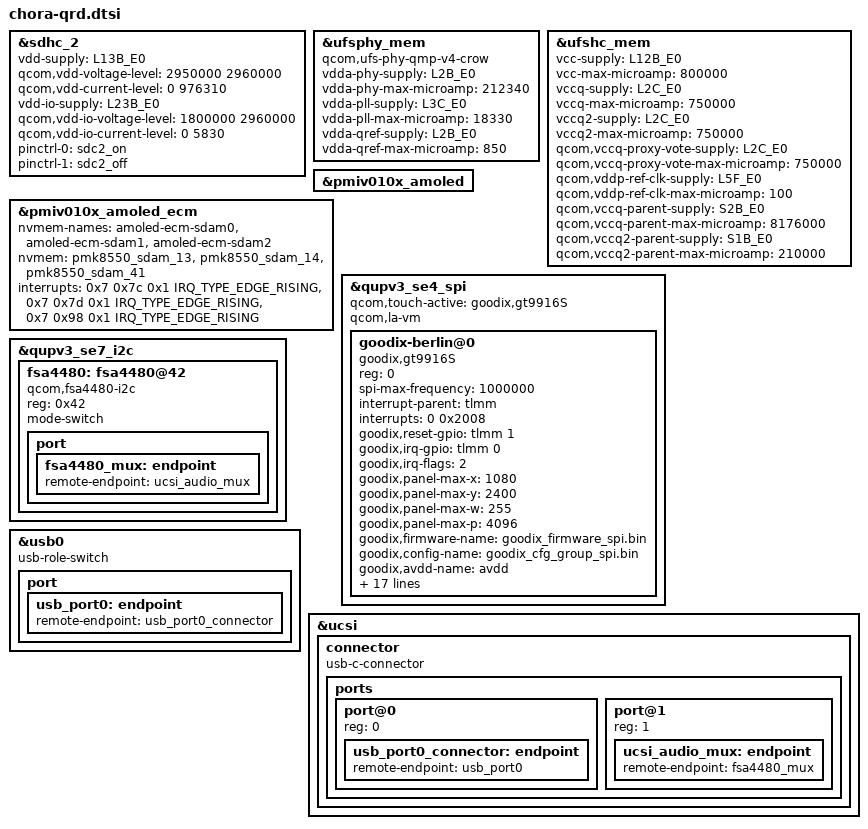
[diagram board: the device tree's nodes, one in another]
// SPDX-License-Identifier: BSD-3-Clause
/*
 * Copyright (c) Qualcomm Technologies, Inc. and/or its subsidiaries.
 */

#include <dt-bindings/gpio/gpio.h>
#include "chora-pmic-overlay.dtsi"
#include "chora-pmiv010x.dtsi"
#include "chora-thermal-overlay.dtsi"

&sdhc_2 {
	vdd-supply = <&L13B_E0>;
	qcom,vdd-voltage-level = <2950000 2960000>;
	qcom,vdd-current-level = <0 976310>;

	vdd-io-supply = <&L23B_E0>;
	qcom,vdd-io-voltage-level = <1800000 2960000>;
	qcom,vdd-io-current-level = <0 5830>;

	pinctrl-names = "default", "sleep";
	pinctrl-0 = <&sdc2_on>;
	pinctrl-1 = <&sdc2_off>;

	status = "ok";
};

&ufsphy_mem {
	compatible = "qcom,ufs-phy-qmp-v4-crow";

	/* VDDA_UFS_CORE */
	vdda-phy-supply = <&L2B_E0>;
	vdda-phy-max-microamp = <212340>;

	/* VDDA_UFS_0_1P2 */
	vdda-pll-supply = <&L3C_E0>;
	vdda-pll-max-microamp = <18330>;

	/* Qref power supply, Refer Qref diagram */
	vdda-qref-supply = <&L2B_E0>;
	vdda-qref-max-microamp = <850>;

	status = "ok";
};

&ufshc_mem {
	vcc-supply = <&L12B_E0>;
	vcc-max-microamp = <800000>;

	vccq-supply = <&L2C_E0>;
	vccq-max-microamp = <750000>;

	vccq2-supply = <&L2C_E0>;
	vccq2-max-microamp = <750000>;

	qcom,vccq-proxy-vote-supply = <&L2C_E0>;
	qcom,vccq-proxy-vote-max-microamp = <750000>;

	qcom,vddp-ref-clk-supply = <&L5F_E0>;
	qcom,vddp-ref-clk-max-microamp = <100>;

	qcom,vccq-parent-supply = <&S2B_E0>;
	qcom,vccq-parent-max-microamp = <8176000>;

	qcom,vccq2-parent-supply = <&S1B_E0>;
	qcom,vccq2-parent-max-microamp = <210000>;

	status = "ok";
};

&pmiv010x_amoled {
	status = "ok";
};


&pmiv010x_amoled_ecm {
	nvmem-names = "amoled-ecm-sdam0", "amoled-ecm-sdam1",
		      "amoled-ecm-sdam2";
	nvmem = <&pmk8550_sdam_13>, <&pmk8550_sdam_14>,
		<&pmk8550_sdam_41>;
	interrupt-names = "ecm-sdam0", "ecm-sdam1",
			  "ecm-sdam2";
	interrupts = <0x7 0x7c 0x1 IRQ_TYPE_EDGE_RISING>,
		     <0x7 0x7d 0x1 IRQ_TYPE_EDGE_RISING>,
		     <0x7 0x98 0x1 IRQ_TYPE_EDGE_RISING>;
	status = "ok";
};

&qupv3_se4_spi {
	#address-cells = <1>;
	#size-cells = <0>;

	qcom,touch-active = "goodix,gt9916S";
	status = "ok";
	qcom,la-vm;

	goodix-berlin@0 {
		compatible = "goodix,gt9916S";
		reg = <0>;
		spi-max-frequency = <1000000>;
		interrupt-parent = <&tlmm>;
		interrupts = <0 0x2008>;
		goodix,reset-gpio = <&tlmm 1 0x00>;
		goodix,irq-gpio = <&tlmm 0 0x2008>;
		goodix,irq-flags = <2>;
		goodix,panel-max-x = <1080>;
		goodix,panel-max-y = <2400>;
		goodix,panel-max-w = <255>;
		goodix,panel-max-p = <4096>;
		goodix,firmware-name = "goodix_firmware_spi.bin";
		goodix,config-name = "goodix_cfg_group_spi.bin";
		goodix,avdd-name = "avdd";
		goodix,iovdd-name = "iovdd";
		avdd-supply = <&L22B>;
		iovdd-supply = <&L9B>;
		pinctrl-names = "pmx_ts_active", "pmx_ts_suspend", "pmx_ts_release";
		pinctrl-0 = <&ts_active>;
		pinctrl-1 = <&ts_int_suspend &ts_reset_suspend>;
		pinctrl-2 = <&ts_release>;
		goodix,touch-type = "primary";
		goodix,qts_en;

		qts,trusted-touch-mode = "vm_mode";
		qts,touch-environment = "pvm";
		qts,trusted-touch-type = "primary";
		qts,trusted-touch-spi-irq = <664>;
		qts,trusted-touch-io-bases = <0xA90000>;
		qts,trusted-touch-io-sizes = <0x1000>;
		qts,trusted-touch-vm-gpio-list = <&tlmm 19 0 &tlmm 20 0 &tlmm 21 0
						&tlmm 22 0 &tlmm 1 0 &tlmm 0 0x2008>;
	};
};

&qupv3_se7_i2c {
	status = "okay";
	fsa4480: fsa4480@42 {
		compatible = "qcom,fsa4480-i2c";
		reg = <0x42>;
	};
};

&fsa4480 {
	mode-switch;

	port {
		fsa4480_mux: endpoint {
			remote-endpoint = <&ucsi_audio_mux>;
		};
	};
};

&usb0 {
	usb-role-switch;

	port {
		usb_port0: endpoint {
			remote-endpoint = <&usb_port0_connector>;
		};
	};
};

&ucsi {
	connector {
		compatible = "usb-c-connector";

		ports {
			#address-cells = <1>;
			#size-cells = <0>;

			port@0 {
				reg = <0>;

				usb_port0_connector: endpoint {
					remote-endpoint = <&usb_port0>;
				};
			};

			port@1 {
				reg = <1>;

				ucsi_audio_mux: endpoint {
					remote-endpoint = <&fsa4480_mux>;
				};
			};
		};
	};
};
